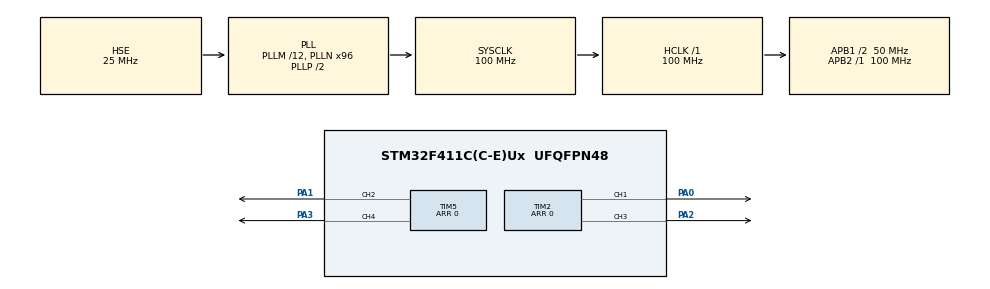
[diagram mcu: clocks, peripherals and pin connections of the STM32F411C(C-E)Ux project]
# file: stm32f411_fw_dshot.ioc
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Mcu.Family=STM32F4
Dma.TIM2_CH1.0.MemInc=DMA_MINC_ENABLE
Dma.TIM5_CH4/TRIG.3.FIFOThreshold=DMA_FIFO_THRESHOLD_1QUARTERFULL
RCC.CortexFreq_Value=100000000
Dma.TIM5_CH2.2.MemInc=DMA_MINC_ENABLE
Dma.TIM5_CH2.2.Instance=DMA1_Stream4
Dma.TIM5_CH4/TRIG.3.PeriphBurst=DMA_PBURST_SINGLE
SH.S_TIM5_CH2.0=TIM5_CH2,PWM Generation2 CH2
Dma.TIM2_CH1.0.Instance=DMA1_Stream5
NVIC.DMA1_Stream4_IRQn=true\:0\:0\:false\:false\:true\:false\:true
RCC.SYSCLKSource=RCC_SYSCLKSOURCE_PLLCLK
ProjectManager.StackSize=0x400
Dma.TIM5_CH2.2.Mode=DMA_NORMAL
Dma.TIM5_CH2.2.FIFOMode=DMA_FIFOMODE_ENABLE
Dma.TIM2_CH3/UP.1.MemBurst=DMA_MBURST_SINGLE
Dma.TIM5_CH2.2.PeriphInc=DMA_PINC_DISABLE
PH0\ -\ OSC_IN.Signal=RCC_OSC_IN
Dma.TIM5_CH4/TRIG.3.FIFOMode=DMA_FIFOMODE_ENABLE
RCC.HCLKFreq_Value=100000000
RCC.APB2TimFreq_Value=100000000
Dma.TIM5_CH4/TRIG.3.Instance=DMA1_Stream3
RCC.AHBFreq_Value=100000000
RCC.HSE_VALUE=25000000
PC14-OSC32_IN.Mode=LSE-External-Oscillator
TIM5.Channel-PWM\ Generation4\ CH4=TIM_CHANNEL_4
PA14.Mode=Serial_Wire
Dma.TIM5_CH4/TRIG.3.MemBurst=DMA_MBURST_SINGLE
TIM2.Channel-PWM\ Generation1\ CH1=TIM_CHANNEL_1
Dma.TIM2_CH1.0.FIFOThreshold=DMA_FIFO_THRESHOLD_1QUARTERFULL
Dma.TIM5_CH2.2.PeriphDataAlignment=DMA_PDATAALIGN_WORD
Dma.TIM2_CH3/UP.1.PeriphBurst=DMA_PBURST_SINGLE
Dma.TIM5_CH2.2.Direction=DMA_MEMORY_TO_PERIPH
Mcu.Package=UFQFPN48
Dma.TIM2_CH1.0.FIFOMode=DMA_FIFOMODE_ENABLE
Dma.TIM2_CH3/UP.1.MemDataAlignment=DMA_MDATAALIGN_WORD
Dma.TIM5_CH4/TRIG.3.Priority=DMA_PRIORITY_HIGH
Dma.TIM5_CH4/TRIG.3.Mode=DMA_NORMAL
Dma.TIM2_CH1.0.PeriphDataAlignment=DMA_PDATAALIGN_WORD
Dma.Request2=TIM5_CH2
Dma.Request1=TIM2_CH3/UP
Dma.TIM2_CH3/UP.1.Direction=DMA_MEMORY_TO_PERIPH
RCC.APB1TimFreq_Value=100000000
Dma.TIM2_CH3/UP.1.Priority=DMA_PRIORITY_HIGH
Dma.Request3=TIM5_CH4/TRIG
Dma.TIM5_CH4/TRIG.3.MemDataAlignment=DMA_MDATAALIGN_WORD
Dma.TIM5_CH4/TRIG.3.Direction=DMA_MEMORY_TO_PERIPH
Dma.Request0=TIM2_CH1
Dma.TIM2_CH1.0.Direction=DMA_MEMORY_TO_PERIPH
PA3.Signal=S_TIM5_CH4
Dma.TIM2_CH3/UP.1.Instance=DMA1_Stream1
RCC.PLLSourceVirtual=RCC_PLLSOURCE_HSE
PC15-OSC32_OUT.Mode=LSE-External-Oscillator
Dma.TIM2_CH3/UP.1.MemInc=DMA_MINC_ENABLE
Dma.TIM2_CH1.0.MemBurst=DMA_MBURST_SINGLE
Dma.TIM5_CH2.2.MemDataAlignment=DMA_MDATAALIGN_WORD
PH1\ -\ OSC_OUT.Mode=HSE-External-Oscillator
NVIC.DMA1_Stream1_IRQn=true\:0\:0\:false\:false\:true\:false\:true
RCC.APB1CLKDivider=RCC_HCLK_DIV2
PC14-OSC32_IN.Signal=RCC_OSC32_IN
Dma.TIM2_CH3/UP.1.Mode=DMA_NORMAL
PA0-WKUP.Signal=S_TIM2_CH1_ETR
PA13.Signal=SYS_JTMS-SWDIO
PH0\ -\ OSC_IN.Mode=HSE-External-Oscillator
Dma.TIM5_CH4/TRIG.3.PeriphDataAlignment=DMA_PDATAALIGN_WORD
ProjectManager.TargetToolchain=STM32CubeIDE
NVIC.DMA1_Stream5_IRQn=true\:0\:0\:false\:false\:true\:false\:true
Dma.TIM2_CH3/UP.1.FIFOMode=DMA_FIFOMODE_ENABLE
Dma.TIM5_CH2.2.MemBurst=DMA_MBURST_SINGLE
PC15-OSC32_OUT.Signal=RCC_OSC32_OUT
PA1.Signal=S_TIM5_CH2
PH1\ -\ OSC_OUT.Signal=RCC_OSC_OUT
board=custom
RCC.VCOOutputFreq_Value=200000000
Dma.TIM5_CH4/TRIG.3.MemInc=DMA_MINC_ENABLE
RCC.APB2Freq_Value=100000000
Dma.TIM2_CH1.0.Priority=DMA_PRIORITY_HIGH
SH.S_TIM2_CH3.0=TIM2_CH3,PWM Generation3 CH3
TIM2.Channel-PWM\ Generation3\ CH3=TIM_CHANNEL_3
SH.S_TIM5_CH4.0=TIM5_CH4,PWM Generation4 CH4
TIM2.Period=0
PA13.Mode=Serial_Wire
Dma.TIM2_CH3/UP.1.PeriphDataAlignment=DMA_PDATAALIGN_WORD
Mcu.Name=STM32F411C(C-E)Ux
PA2.Signal=S_TIM2_CH3
Dma.TIM5_CH2.2.PeriphBurst=DMA_PBURST_SINGLE
RCC.48MHZClocksFreq_Value=50000000
TIM5.Channel-PWM\ Generation2\ CH2=TIM_CHANNEL_2
RCC.SYSCLKFreq_VALUE=100000000
Dma.TIM2_CH1.0.Mode=DMA_NORMAL
Dma.TIM2_CH1.0.PeriphBurst=DMA_PBURST_SINGLE
SH.S_TIM2_CH1_ETR.0=TIM2_CH1,PWM Generation1 CH1
Dma.TIM2_CH1.0.MemDataAlignment=DMA_MDATAALIGN_WORD
PA14.Signal=SYS_JTCK-SWCLK
Dma.TIM2_CH3/UP.1.PeriphInc=DMA_PINC_DISABLE
ProjectManager.HeapSize=0x200
Dma.TIM5_CH4/TRIG.3.PeriphInc=DMA_PINC_DISABLE
RCC.HSI_VALUE=16000000
NVIC.PriorityGroup=NVIC_PRIORITYGROUP_4
Dma.TIM5_CH2.2.Priority=DMA_PRIORITY_HIGH
RCC.PLLM=12
RCC.PLLN=96
Dma.TIM2_CH3/UP.1.FIFOThreshold=DMA_FIFO_THRESHOLD_1QUARTERFULL
NVIC.DMA1_Stream3_IRQn=true\:0\:0\:false\:false\:true\:false\:true
TIM5.Period=0
RCC.APB1Freq_Value=50000000
Dma.TIM5_CH2.2.FIFOThreshold=DMA_FIFO_THRESHOLD_1QUARTERFULL
Dma.TIM2_CH1.0.PeriphInc=DMA_PINC_DISABLE

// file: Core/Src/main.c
/* USER CODE BEGIN Header */
/**
  ******************************************************************************
  * @file           : main.c
  * @brief          : Main program body
  ******************************************************************************
  * @attention
  *
  * <h2><center>&copy; Copyright (c) 2021 STMicroelectronics.
  * All rights reserved.</center></h2>
  *
  * This software component is licensed by ST under BSD 3-Clause license,
  * the "License"; You may not use this file except in compliance with the
  * License. You may obtain a copy of the License at:
  *                        opensource.org/licenses/BSD-3-Clause
  *
  ******************************************************************************
  */
/* USER CODE END Header */
#include "main.h"
#include "dma.h"
#include "tim.h"
#include "gpio.h"

/* USER CODE BEGIN Includes */

#include "dshot.h"

/* USER CODE END Includes */

/* USER CODE BEGIN PV */

uint16_t my_motor_value[4] = {0, 0, 0, 0};

/* USER CODE END PV */

void SystemClock_Config(void);

int main(void)
{

  /* MCU Configuration--------------------------------------------------------*/

  /* Reset of all peripherals, Initializes the Flash interface and the Systick. */
  HAL_Init();

  /* Configure the system clock */
  SystemClock_Config();

  /* Initialize all configured peripherals */
  MX_GPIO_Init();
  MX_DMA_Init();
  MX_TIM2_Init();
  MX_TIM5_Init();
  /* USER CODE BEGIN 2 */

  dshot_init(DSHOT600);

  /* USER CODE END 2 */

  /* Infinite loop */
  while (1)
  {

    /* USER CODE BEGIN 3 */

	  dshot_write(my_motor_value);
	  HAL_Delay(1);
  }
  /* USER CODE END 3 */
}

void SystemClock_Config(void)
{
  RCC_OscInitTypeDef RCC_OscInitStruct = {0};
  RCC_ClkInitTypeDef RCC_ClkInitStruct = {0};

  /** Configure the main internal regulator output voltage
  */
  __HAL_RCC_PWR_CLK_ENABLE();
  __HAL_PWR_VOLTAGESCALING_CONFIG(PWR_REGULATOR_VOLTAGE_SCALE1);
  /** Initializes the RCC Oscillators according to the specified parameters
  * in the RCC_OscInitTypeDef structure.
  */
  RCC_OscInitStruct.OscillatorType = RCC_OSCILLATORTYPE_HSE;
  RCC_OscInitStruct.HSEState = RCC_HSE_ON;
  RCC_OscInitStruct.PLL.PLLState = RCC_PLL_ON;
  RCC_OscInitStruct.PLL.PLLSource = RCC_PLLSOURCE_HSE;
  RCC_OscInitStruct.PLL.PLLM = 12;
  RCC_OscInitStruct.PLL.PLLN = 96;
  RCC_OscInitStruct.PLL.PLLP = RCC_PLLP_DIV2;
  RCC_OscInitStruct.PLL.PLLQ = 4;
  if (HAL_RCC_OscConfig(&RCC_OscInitStruct) != HAL_OK)
  {
    Error_Handler();
  }
  /** Initializes the CPU, AHB and APB buses clocks
  */
  RCC_ClkInitStruct.ClockType = RCC_CLOCKTYPE_HCLK|RCC_CLOCKTYPE_SYSCLK
                              |RCC_CLOCKTYPE_PCLK1|RCC_CLOCKTYPE_PCLK2;
  RCC_ClkInitStruct.SYSCLKSource = RCC_SYSCLKSOURCE_PLLCLK;
  RCC_ClkInitStruct.AHBCLKDivider = RCC_SYSCLK_DIV1;
  RCC_ClkInitStruct.APB1CLKDivider = RCC_HCLK_DIV2;
  RCC_ClkInitStruct.APB2CLKDivider = RCC_HCLK_DIV1;

  if (HAL_RCC_ClockConfig(&RCC_ClkInitStruct, FLASH_LATENCY_3) != HAL_OK)
  {
    Error_Handler();
  }
}

void Error_Handler(void)
{
  __disable_irq();
  while (1)
  {
  }
}

/************************ (C) COPYRIGHT STMicroelectronics *****END OF FILE****/
